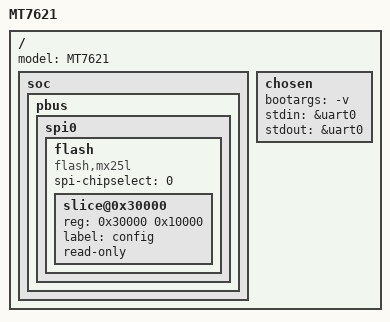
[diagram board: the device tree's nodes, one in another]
/*
 * Copyright (c) 2016, Stanislav Galabov
 */

/dts-v1/;
/include/ "mt7621.dtsi"

/ {
	model = "MT7621";

	soc {
            pbus {
                spi0 {
                        flash {
                                compatible = "flash,mx25l";
                                spi-chipselect = <0>;
                                #address-cells = <1>;
                                #size-cells = <1>;

                                slice@0x30000 {
                                        reg = <0x30000 0x10000>;
                                        label = "config";
                                        read-only;
                                };
                        };
                };
            };
	};

	chosen {
		bootargs = "-v";
		stdin = &uart0;
		stdout = &uart0;
	};

};

